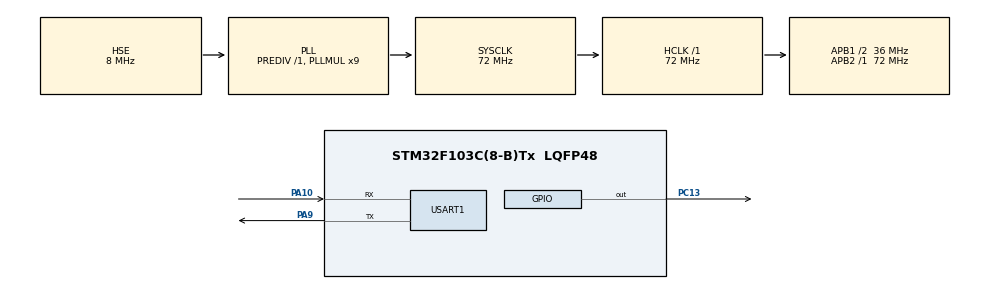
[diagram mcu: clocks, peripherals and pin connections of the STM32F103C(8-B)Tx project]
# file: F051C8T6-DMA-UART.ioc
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Dma.Request0=USART1_TX
Dma.USART1_TX.0.Direction=DMA_MEMORY_TO_PERIPH
Dma.USART1_TX.0.Instance=DMA1_Channel4
Dma.USART1_TX.0.MemDataAlignment=DMA_MDATAALIGN_BYTE
Dma.USART1_TX.0.MemInc=DMA_MINC_ENABLE
Dma.USART1_TX.0.Mode=DMA_CIRCULAR
Dma.USART1_TX.0.PeriphDataAlignment=DMA_PDATAALIGN_BYTE
Dma.USART1_TX.0.PeriphInc=DMA_PINC_DISABLE
Dma.USART1_TX.0.Priority=DMA_PRIORITY_MEDIUM
Mcu.Family=STM32F1
Mcu.Name=STM32F103C(8-B)Tx
Mcu.Package=LQFP48
NVIC.DMA1_Channel4_IRQn=true\:0\:0\:false
NVIC.PriorityGroup=NVIC_PRIORITYGROUP_4
NVIC.USART1_IRQn=true\:0\:0\:false
PA10.Mode=Asynchronous
PA10.Signal=USART1_RX
PA9.Mode=Asynchronous
PA9.Signal=USART1_TX
PC13-TAMPER-RTC.Signal=GPIO_Output
PD0-OSC_IN.Mode=HSE-External-Oscillator
PD0-OSC_IN.Signal=RCC_OSC_IN
PD1-OSC_OUT.Mode=HSE-External-Oscillator
PD1-OSC_OUT.Signal=RCC_OSC_OUT
ProjectManager.TargetToolchain=MDK-ARM V5
RCC.AHBFreq_Value=72000000
RCC.APB1CLKDivider=RCC_HCLK_DIV2
RCC.APB1Freq_Value=36000000
RCC.APB1TimCLKDivider=1
RCC.APB1TimFreq_Value=36000000
RCC.APB2Freq_Value=72000000
RCC.APB2TimFreq_Value=72000000
RCC.HCLKFreq_Value=72000000
RCC.HSIState=RCC_HSI_ON
RCC.PLLMUL=RCC_PLL_MUL9
RCC.PLLSourceVirtual=RCC_PLLSOURCE_HSE
RCC.SYSCLKFreq_VALUE=72000000
RCC.SYSCLKSource=RCC_SYSCLKSOURCE_PLLCLK
RCC.USBFreq_Value=72000000
board=F051C8T6-DMA-UART

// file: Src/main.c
/**
  ******************************************************************************
  * File Name          : main.c
  * Description        : Main program body
  ******************************************************************************
  *
  * COPYRIGHT(c) 2015 STMicroelectronics
  *
  * Redistribution and use in source and binary forms, with or without modification,
  * are permitted provided that the following conditions are met:
  *   1. Redistributions of source code must retain the above copyright notice,
  *      this list of conditions and the following disclaimer.
  *   2. Redistributions in binary form must reproduce the above copyright notice,
  *      this list of conditions and the following disclaimer in the documentation
  *      and/or other materials provided with the distribution.
  *   3. Neither the name of STMicroelectronics nor the names of its contributors
  *      may be used to endorse or promote products derived from this software
  *      without specific prior written permission.
  *
  * THIS SOFTWARE IS PROVIDED BY THE COPYRIGHT HOLDERS AND CONTRIBUTORS "AS IS"
  * AND ANY EXPRESS OR IMPLIED WARRANTIES, INCLUDING, BUT NOT LIMITED TO, THE
  * IMPLIED WARRANTIES OF MERCHANTABILITY AND FITNESS FOR A PARTICULAR PURPOSE ARE
  * DISCLAIMED. IN NO EVENT SHALL THE COPYRIGHT HOLDER OR CONTRIBUTORS BE LIABLE
  * FOR ANY DIRECT, INDIRECT, INCIDENTAL, SPECIAL, EXEMPLARY, OR CONSEQUENTIAL
  * DAMAGES (INCLUDING, BUT NOT LIMITED TO, PROCUREMENT OF SUBSTITUTE GOODS OR
  * SERVICES; LOSS OF USE, DATA, OR PROFITS; OR BUSINESS INTERRUPTION) HOWEVER
  * CAUSED AND ON ANY THEORY OF LIABILITY, WHETHER IN CONTRACT, STRICT LIABILITY,
  * OR TORT (INCLUDING NEGLIGENCE OR OTHERWISE) ARISING IN ANY WAY OUT OF THE USE
  * OF THIS SOFTWARE, EVEN IF ADVISED OF THE POSSIBILITY OF SUCH DAMAGE.
  *
  ******************************************************************************
  */
#include "stm32f1xx_hal.h"
#include "dma.h"
#include "usart.h"
#include "gpio.h"

/* USER CODE BEGIN Includes */
#define TXBUFFERSIZE                      (COUNTOF(aTxBuffer) - 1)
#define RXBUFFERSIZE                      TXBUFFERSIZE
#define COUNTOF(__BUFFER__)   (sizeof(__BUFFER__) / sizeof(*(__BUFFER__)))

/* USER CODE END Includes */

/* USER CODE BEGIN PV */
/* Private variables ---------------------------------------------------------*/

uint8_t aTxBuffer[] = "Hallo ICH BIN CHENYI\n\r";
/* USER CODE END PV */

void SystemClock_Config(void);

/* USER CODE BEGIN PFP */
/* Private function prototypes -----------------------------------------------*/

/* USER CODE END PFP */

int main(void)
{

  /* MCU Configuration----------------------------------------------------------*/

  /* Reset of all peripherals, Initializes the Flash interface and the Systick. */
  HAL_Init();

  /* Configure the system clock */
  SystemClock_Config();

  /* Initialize all configured peripherals */
  MX_GPIO_Init();
  MX_DMA_Init();
  MX_USART1_UART_Init();

  /* USER CODE BEGIN 2 */
	HAL_UART_Transmit_DMA(&huart1, (uint8_t*)aTxBuffer,TXBUFFERSIZE);
  /* USER CODE END 2 */

  /* Infinite loop */
  while (1)
  {

  /* USER CODE BEGIN 3 */
//  HAL_Delay(500);
//	HAL_GPIO_TogglePin(GPIOC, GPIO_PIN_13);
	HAL_Delay(1000);

	HAL_GPIO_TogglePin(GPIOC, GPIO_PIN_13);
  }
  /* USER CODE END 3 */

}

/** System Clock Configuration
*/
void SystemClock_Config(void)
{

  RCC_OscInitTypeDef RCC_OscInitStruct;
  RCC_ClkInitTypeDef RCC_ClkInitStruct;

  RCC_OscInitStruct.OscillatorType = RCC_OSCILLATORTYPE_HSE;
  RCC_OscInitStruct.HSEState = RCC_HSE_ON;
  RCC_OscInitStruct.HSEPredivValue = RCC_HSE_PREDIV_DIV1;
  RCC_OscInitStruct.PLL.PLLState = RCC_PLL_ON;
  RCC_OscInitStruct.PLL.PLLSource = RCC_PLLSOURCE_HSE;
  RCC_OscInitStruct.PLL.PLLMUL = RCC_PLL_MUL9;
  HAL_RCC_OscConfig(&RCC_OscInitStruct);

  RCC_ClkInitStruct.ClockType = RCC_CLOCKTYPE_SYSCLK|RCC_CLOCKTYPE_PCLK1;
  RCC_ClkInitStruct.SYSCLKSource = RCC_SYSCLKSOURCE_PLLCLK;
  RCC_ClkInitStruct.AHBCLKDivider = RCC_SYSCLK_DIV1;
  RCC_ClkInitStruct.APB1CLKDivider = RCC_HCLK_DIV2;
  RCC_ClkInitStruct.APB2CLKDivider = RCC_HCLK_DIV1;
  HAL_RCC_ClockConfig(&RCC_ClkInitStruct, FLASH_LATENCY_2);

  HAL_SYSTICK_Config(HAL_RCC_GetHCLKFreq()/1000);

  HAL_SYSTICK_CLKSourceConfig(SYSTICK_CLKSOURCE_HCLK);

}

/************************ (C) COPYRIGHT STMicroelectronics *****END OF FILE****/
